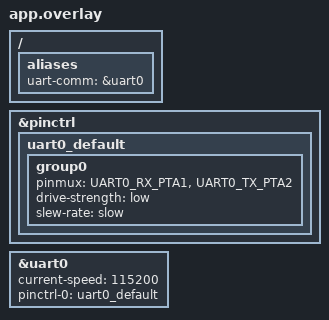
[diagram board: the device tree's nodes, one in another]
/ {
	aliases {
		uart-comm = &uart0;
	};
};

&pinctrl {
	uart0_default: uart0_default {
		group0 {
			pinmux = <UART0_RX_PTA1>, <UART0_TX_PTA2>;
			drive-strength = "low";
			slew-rate = "slow";
		};
	};
};

&uart0 {
	status = "okay";
	current-speed = <115200>;
	pinctrl-0 = <&uart0_default>;
	pinctrl-names = "default";
};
